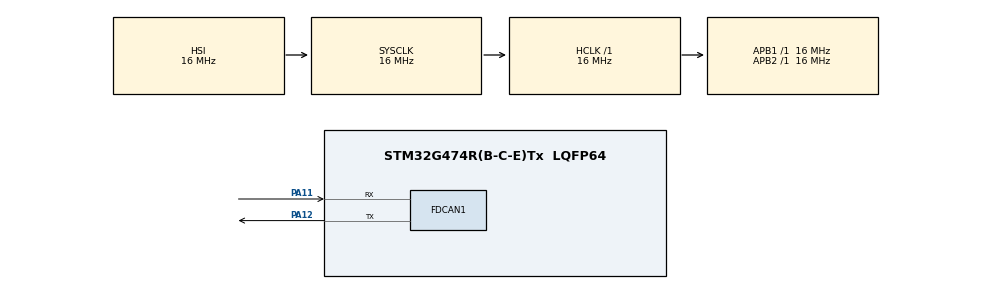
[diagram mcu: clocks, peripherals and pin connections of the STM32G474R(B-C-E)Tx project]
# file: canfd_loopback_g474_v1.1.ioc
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FDCAN1.AutoRetransmission=ENABLE
FDCAN1.CalculateBaudRateNominal=1000000
FDCAN1.CalculateTimeBitNominal=1000
FDCAN1.CalculateTimeQuantumNominal=62.5
FDCAN1.ClockDivider=FDCAN_CLOCK_DIV1
FDCAN1.DataTimeSeg1=13
FDCAN1.DataTimeSeg2=2
FDCAN1.FrameFormat=FDCAN_FRAME_FD_NO_BRS
FDCAN1.Mode=FDCAN_MODE_INTERNAL_LOOPBACK
FDCAN1.NominalPrescaler=1
FDCAN1.NominalTimeSeg1=13
FDCAN1.NominalTimeSeg2=2
FDCAN1.StdFiltersNbr=1
Mcu.Family=STM32G4
Mcu.Name=STM32G474R(B-C-E)Tx
Mcu.Package=LQFP64
NVIC.FDCAN1_IT0_IRQn=true\:0\:0\:false\:false\:true\:true\:true\:true
NVIC.PriorityGroup=NVIC_PRIORITYGROUP_4
PA11.Mode=FDCAN_Activate
PA11.Signal=FDCAN1_RX
PA12.Mode=FDCAN_Activate
PA12.Signal=FDCAN1_TX
ProjectManager.HeapSize=0x200
ProjectManager.StackSize=0x400
ProjectManager.TargetToolchain=STM32CubeIDE
RCC.AHBFreq_Value=16000000
RCC.APB1Freq_Value=16000000
RCC.APB1TimFreq_Value=16000000
RCC.APB2Freq_Value=16000000
RCC.APB2TimFreq_Value=16000000
RCC.CortexFreq_Value=16000000
RCC.EXTERNAL_CLOCK_VALUE=12288000
RCC.HCLKFreq_Value=16000000
RCC.HSE_VALUE=8000000
RCC.HSI48_VALUE=48000000
RCC.HSI_VALUE=16000000
RCC.LSE_VALUE=32768
RCC.SYSCLKFreq_VALUE=16000000
RCC.USBFreq_Value=64000000
RCC.VCOOutputFreq_Value=128000000
VP_SYS_VS_DBSignals.Mode=DisableDeadBatterySignals
board=custom

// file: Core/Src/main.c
/* USER CODE BEGIN Header */
/**
  ******************************************************************************
  * @file           : main.c
  * @brief          : Main program body
  ******************************************************************************
  * @attention
  *
  * Copyright (c) 2026 STMicroelectronics.
  * All rights reserved.
  *
  * This software is licensed under terms that can be found in the LICENSE file
  * in the root directory of this software component.
  * If no LICENSE file comes with this software, it is provided AS-IS.
  *
  ******************************************************************************
  */
/* USER CODE END Header */
#include "main.h"

/* USER CODE BEGIN Includes */
#include <string.h>    /* needed for memcmp() */
/* USER CODE END Includes */

FDCAN_HandleTypeDef hfdcan1;

/* USER CODE BEGIN PV */
FDCAN_FilterTypeDef   sFilterConfig;
FDCAN_TxHeaderTypeDef TxHeader;
FDCAN_RxHeaderTypeDef RxHeader;

uint8_t TxData[8] = {0xCA, 0xFE, 0xBE, 0xEF, 0x01, 0x02, 0x03, 0x04};
uint8_t RxData[8] = {0};
volatile uint8_t testPassed = 0;  /* volatile = always written to RAM */
/* USER CODE END PV */

void SystemClock_Config(void);
static void MX_GPIO_Init(void);
static void MX_FDCAN1_Init(void);

int main(void)
{

  /* MCU Configuration--------------------------------------------------------*/

  /* Reset of all peripherals, Initializes the Flash interface and the Systick. */
  HAL_Init();

  /* Configure the system clock */
  SystemClock_Config();

  /* Initialize all configured peripherals */
  MX_GPIO_Init();
  MX_FDCAN1_Init();
  /* USER CODE BEGIN 2 */
  /* Step 1: Configure receive filter */
  sFilterConfig.IdType       = FDCAN_STANDARD_ID;
  sFilterConfig.FilterIndex  = 0;
  sFilterConfig.FilterType   = FDCAN_FILTER_MASK;
  sFilterConfig.FilterConfig = FDCAN_FILTER_TO_RXFIFO0;
  sFilterConfig.FilterID1    = 0x111;   /* ID to accept */
  sFilterConfig.FilterID2    = 0x7FF;   /* mask: exact match */

  if (HAL_FDCAN_ConfigFilter(&hfdcan1, &sFilterConfig) != HAL_OK)
    Error_Handler();

  /* Step 2: Reject everything else */
  HAL_FDCAN_ConfigGlobalFilter(&hfdcan1,
    FDCAN_REJECT, FDCAN_REJECT,
    FDCAN_REJECT_REMOTE, FDCAN_REJECT_REMOTE);

  /* Step 3: Start FDCAN */
  if (HAL_FDCAN_Start(&hfdcan1) != HAL_OK)
    Error_Handler();
  /* USER CODE END 2 */

  /* Infinite loop */
  /* USER CODE BEGIN WHILE */
  while (1)
  {
	  /* Step 4: Build and transmit a frame */
	  TxHeader.Identifier          = 0x111;
	  TxHeader.IdType              = FDCAN_STANDARD_ID;
	  TxHeader.TxFrameType         = FDCAN_DATA_FRAME;
	  TxHeader.DataLength          = FDCAN_DLC_BYTES_8;
	  TxHeader.ErrorStateIndicator = FDCAN_ESI_ACTIVE;
	  TxHeader.BitRateSwitch       = FDCAN_BRS_OFF;
	  TxHeader.FDFormat            = FDCAN_FD_CAN;
	  TxHeader.TxEventFifoControl  = FDCAN_NO_TX_EVENTS;
	  TxHeader.MessageMarker       = 0;

	  if (HAL_FDCAN_AddMessageToTxFifoQ(&hfdcan1, &TxHeader, TxData) != HAL_OK)
	    Error_Handler();

    /* USER CODE END WHILE */

    /* USER CODE BEGIN 3 */
	  /* Step 5: Wait, then read back from RX FIFO */
	   HAL_Delay(10);

	   if (HAL_FDCAN_GetRxFifoFillLevel(&hfdcan1, FDCAN_RX_FIFO0) > 0)
	   {
	     HAL_FDCAN_GetRxMessage(&hfdcan1, FDCAN_RX_FIFO0, &RxHeader, RxData);

	     if (memcmp(TxData, RxData, 8) == 0)
	     {
	       testPassed = 1;   /* <-- PUT YOUR BREAKPOINT ON THIS LINE */
	     }
	   }

	   HAL_Delay(500);   /* send once every 500ms, don't spam */

  }
  /* USER CODE END 3 */
}

void SystemClock_Config(void)
{
  RCC_OscInitTypeDef RCC_OscInitStruct = {0};
  RCC_ClkInitTypeDef RCC_ClkInitStruct = {0};

  /** Configure the main internal regulator output voltage
  */
  HAL_PWREx_ControlVoltageScaling(PWR_REGULATOR_VOLTAGE_SCALE1);

  /** Initializes the RCC Oscillators according to the specified parameters
  * in the RCC_OscInitTypeDef structure.
  */
  RCC_OscInitStruct.OscillatorType = RCC_OSCILLATORTYPE_HSI;
  RCC_OscInitStruct.HSIState = RCC_HSI_ON;
  RCC_OscInitStruct.HSICalibrationValue = RCC_HSICALIBRATION_DEFAULT;
  RCC_OscInitStruct.PLL.PLLState = RCC_PLL_NONE;
  if (HAL_RCC_OscConfig(&RCC_OscInitStruct) != HAL_OK)
  {
    Error_Handler();
  }

  /** Initializes the CPU, AHB and APB buses clocks
  */
  RCC_ClkInitStruct.ClockType = RCC_CLOCKTYPE_HCLK|RCC_CLOCKTYPE_SYSCLK
                              |RCC_CLOCKTYPE_PCLK1|RCC_CLOCKTYPE_PCLK2;
  RCC_ClkInitStruct.SYSCLKSource = RCC_SYSCLKSOURCE_HSI;
  RCC_ClkInitStruct.AHBCLKDivider = RCC_SYSCLK_DIV1;
  RCC_ClkInitStruct.APB1CLKDivider = RCC_HCLK_DIV1;
  RCC_ClkInitStruct.APB2CLKDivider = RCC_HCLK_DIV1;

  if (HAL_RCC_ClockConfig(&RCC_ClkInitStruct, FLASH_LATENCY_0) != HAL_OK)
  {
    Error_Handler();
  }
}

static void MX_FDCAN1_Init(void)
{

  hfdcan1.Instance = FDCAN1;
  hfdcan1.Init.ClockDivider = FDCAN_CLOCK_DIV1;
  hfdcan1.Init.FrameFormat = FDCAN_FRAME_FD_NO_BRS;
  hfdcan1.Init.Mode = FDCAN_MODE_INTERNAL_LOOPBACK;
  hfdcan1.Init.AutoRetransmission = ENABLE;
  hfdcan1.Init.TransmitPause = DISABLE;
  hfdcan1.Init.ProtocolException = DISABLE;
  hfdcan1.Init.NominalPrescaler = 1;
  hfdcan1.Init.NominalSyncJumpWidth = 1;
  hfdcan1.Init.NominalTimeSeg1 = 13;
  hfdcan1.Init.NominalTimeSeg2 = 2;
  hfdcan1.Init.DataPrescaler = 1;
  hfdcan1.Init.DataSyncJumpWidth = 1;
  hfdcan1.Init.DataTimeSeg1 = 13;
  hfdcan1.Init.DataTimeSeg2 = 2;
  hfdcan1.Init.StdFiltersNbr = 1;
  hfdcan1.Init.ExtFiltersNbr = 0;
  hfdcan1.Init.TxFifoQueueMode = FDCAN_TX_FIFO_OPERATION;
  if (HAL_FDCAN_Init(&hfdcan1) != HAL_OK)
  {
    Error_Handler();
  }

}

static void MX_GPIO_Init(void)
{

  /* GPIO Ports Clock Enable */
  __HAL_RCC_GPIOA_CLK_ENABLE();

}

void Error_Handler(void)
{
  __disable_irq();
  while (1)
  {
  }
}
